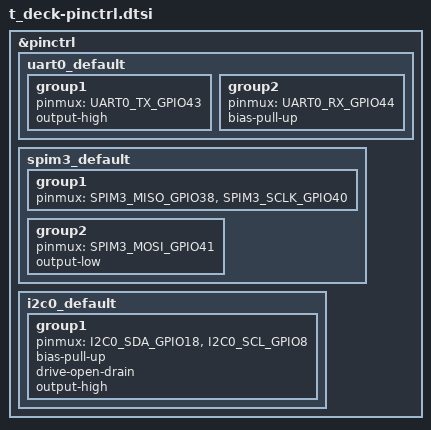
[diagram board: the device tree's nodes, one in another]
/* SPDX-License-Identifier: GPL-3.0-or-later */
/* SPDX-FileCopyrightText: The contributors to the LICHEN project */

#include <zephyr/dt-bindings/pinctrl/esp-pinctrl-common.h>
#include <dt-bindings/pinctrl/esp32s3-pinctrl.h>
#include <zephyr/dt-bindings/pinctrl/esp32s3-gpio-sigmap.h>

&pinctrl {
	uart0_default: uart0_default {
		group1 {
			pinmux = <UART0_TX_GPIO43>;
			output-high;
		};
		group2 {
			pinmux = <UART0_RX_GPIO44>;
			bias-pull-up;
		};
	};

	spim3_default: spim3_default {
		group1 {
			pinmux = <SPIM3_MISO_GPIO38>,
				 <SPIM3_SCLK_GPIO40>;
		};
		group2 {
			pinmux = <SPIM3_MOSI_GPIO41>;
			output-low;
		};
	};

	/*
	 * I2C0 for T-Deck keyboard (addr 0x55): SDA=GPIO18, SCL=GPIO8
	 * (from LilyGO utilities.h BOARD_I2C_SDA/SCL and Keyboard_ESP32C3).
	 * Trackball uses separate GPIOs per BOARD_TBOX_G0* defines (see 
	 * t_deck_esp32s3_procpu.dts comment and utilities.h); not on this bus.
	 * Disabled until input driver validation (see codereview beads).
	 */
	i2c0_default: i2c0_default {
		group1 {
			pinmux = <I2C0_SDA_GPIO18>,
				 <I2C0_SCL_GPIO8>;
			bias-pull-up;
			drive-open-drain;
			output-high;
		};
	};
};
